# STM32WB06 register map
File version: 1.0
CPU: CM0+ r0p0, little endian, MPU, no FPU, 2 interrupt priority bits
Registers are 32-bit, read-write, reset 0x0 unless marked. A register's access mark holds for its fields unless they carry their own. Offsets are from the block's base; [hi:lo] are bit positions; {n}, {i} and the like mark numbered series.

## PKA
Base 0x48300000
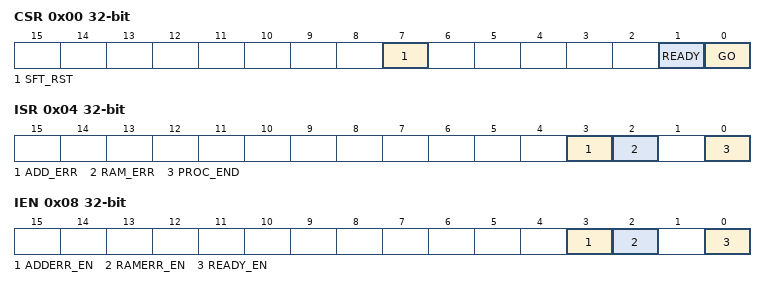
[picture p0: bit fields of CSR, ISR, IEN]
0x00 CSR — PKA_CSR register
  [7] SFT_RST — PKA software reset. Writing 0 clears the bit and releases the PKA block reset. Writing 1 resets the PKA block. The PKA RAM content is not changed.
  [1] READY ro — PKA readiness status. 0: The PKA is still computing 1: The PKA is ready to start a new calculation
  [0] GO — PKA start processing command. Writing 0 has no effect Writing 1 starts the encryption engine
0x04 ISR — PKA_ISR register
  [3] ADD_ERR — AHB Address error interrupt.
  [2] RAM_ERR — RAM read / write access error interrupt.
  [0] PROC_END — PKA process ending interrupt. When read: 0: No new event detected 1: The PKA process is ended (This bit is set to 1 when the PKA_CSR.READY bit rises.) When written: To clear the pending interrupt, the user must write this bit to 1 and clear it just after by writing 0. If the write 0 does not occur, the interrupt is generated on next event towards the CPU if enabled in PKA_IER but the flag is seen at 0 when the interrupt handler reads it in this register (as clear action is still active).
0x08 IEN — PKA_IEN register
  [3] ADDERR_EN — AHB Address error interrupt enable.
  [2] RAMERR_EN — RAM access error interrupt enable.
  [0] READY_EN — READY interrupt enable.

## GPIOB
Base 0x48100000
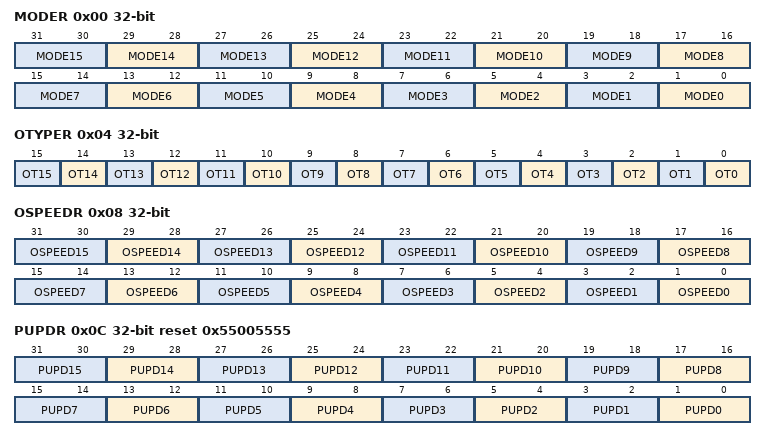
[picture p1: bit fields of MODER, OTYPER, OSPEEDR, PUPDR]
0x00 MODER
  [2n+1:2n] MODE{n} (n=0..15) — Port x configuration pin {n}
    0=Input mode; 1=Output (General purpose output mode); 2=Alternate function mode; 3=Analog mode
0x04 OTYPER
  [n] OT{n} (n=0..15) — Port x configuration pin {n}
    0=PushPull (Output push-pull (reset state)); 1=OpenDrain (Output open-drain)
0x08 OSPEEDR
  [2n+1:2n] OSPEED{n} (n=0..15) — Port x configuration pin {n}
    0=LowSpeed; 1=MediumSpeed; 2=HighSpeed; 3=VeryHighSpeed
0x0C PUPDR reset 0x55005555
  [2n+1:2n] PUPD{n} (n=0..15) — Port x configuration pin {n}
    0=Floating (No pull-up, pull-down); 1=PullUp; 2=PullDown
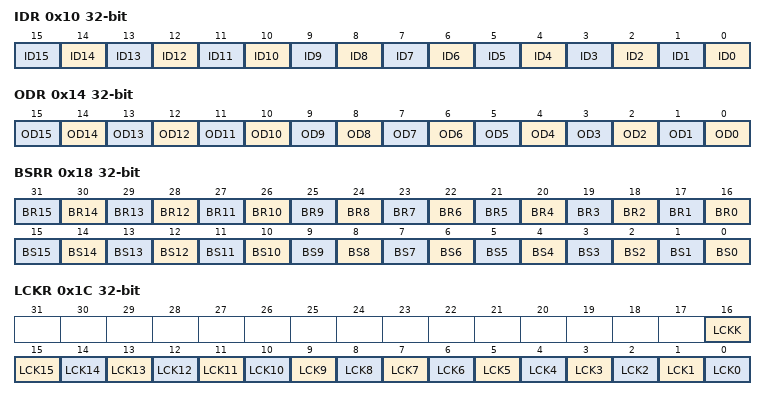
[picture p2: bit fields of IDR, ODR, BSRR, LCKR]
0x10 IDR ro (reset mask 0xFFFF0000)
  [n] ID{n} (n=0..15) — Port input data pin {n}
    0=Low (Input is logic low); 1=High (Input is logic high)
0x14 ODR
  [n] OD{n} (n=0..15) — Port output data pin {n}
    0=Low (Set output to logic low); 1=High (Set output to logic high)
0x18 BSRR wo
  [n+16] BR{n} (n=0..15) — Port x reset pin {n}
    1=Resets the corresponding ODx bit
  [n] BS{n} (n=0..15) — Port x set pin {n}
    1=Set (Sets the corresponding ODx bit)
0x1C LCKR
  [16] LCKK — Lock key This bit can be read any time. It can only be modified using the lock key write sequence. LOCK key write sequence: WR LCKR[16] = '1' + LCKR[15:0] WR LCKR[16] = '0' + LCKR[15:0] WR LCKR[16] = '1' + LCKR[15:0] RD LCKR RD LCKR[16] = '1' (this read operation is optional but it confirms that the lock is active) Note: During the LOCK key write sequence, the value of LCK[15:0] must not change. Note: Any error in the lock sequence aborts the lock. Note: After the first lock sequence on any bit of the port, any read access on the LCKK bit returns '1' until the next MCU reset or peripheral reset.
    0=NotActive (Port configuration lock key not active); 1=Active (Port configuration lock key active)
  [n] LCK{n} (n=0..15) — Port x lock pin {n}
    0=Unlocked (Port configuration not locked); 1=Locked (Port configuration locked)
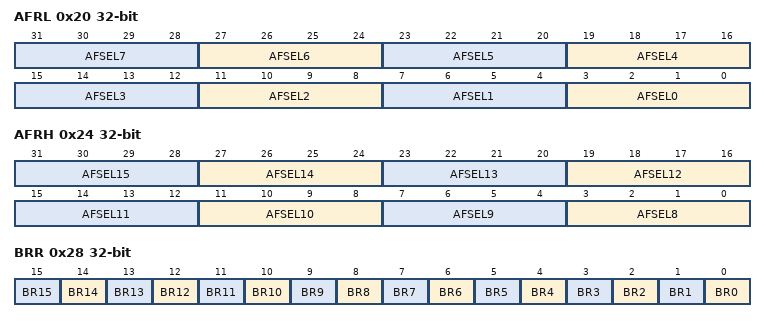
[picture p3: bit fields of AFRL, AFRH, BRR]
0x20 AFRL
  [4n+3:4n] AFSEL{n} (n=0..7) — Alternate function selection for port x I/O pin y These bits are written by software to configure alternate function I/Os.
    {v}=AF{v} (v=0..15)
0x24 AFRH
  [4n-29:4n-32] AFSEL{n} (n=8..15) — Alternate function selection for port x I/O pin y These bits are written by software to configure alternate function I/Os.
    {v}=AF{v} (v=0..15)
0x28 BRR wo
  [n] BR{n} (n=0..15) — Port x reset pin {n}
    0=No action on the corresponding ODx bit; 1=Reset the ODx bit

## IWDG
Base 0x40003000
0x00 KR 16-bit — IWDG_KR register
  [15:0] KEY wo — Key value. Software can only write these bits. Reading returns the reset value. These bits must be written by software at regular intervals with the key value 0xAAAA, otherwise the watchdog generates a reset when the counter reaches 0. Writing the key value 0x5555 to enables access to the IWDG_PR, IWDG_RLR and IWDG_WINR registers. Writing the key value CCCCh starts the watchdog
    0x5555=Unlock (Enable access to PR, RLR and WINR registers); 0xAAAA=Feed watchdog with RLR register value; 0xCCCC=Start the watchdog
0x04 PR 16-bit — IWDG_PR register
  [2:0] PR — Prescaler divider. Set and reset by software. These bits are write access protected. They are written by software to select the prescaler divider feeding the counter clock. PVU bit of IWDG_SR must be reset in order to be able to change the prescaler divider. 000: divider/4 001: divider/8 010: divider/16 011: divider/32 100: divider/64 101: divider/128 110: divider/256 111: divider/256
    0=DivideBy4 (Divider /4); 1=DivideBy8 (Divider /8); 2=DivideBy16 (Divider /16); 3=DivideBy32 (Divider /32); 4=DivideBy64 (Divider /64); 5=DivideBy128 (Divider /128); other=DivideBy256 (Divider /256)
0x08 RLR 16-bit reset 0xFFF — IWDG_RLR register
  [11:0] RL — Watchdog counter reload value. Set and reset by software. These bits are write access protected. They are written by software to define the value to be loaded in the watchdog counter each time the value 0xAAAA is written in the IWDG_KR register. The watchdog counter counts down from this value. The timeout period is a function of this value and the clock prescaler. The RVU bit in the IWDG_SR register must be reset in order to be able to change the reload value.
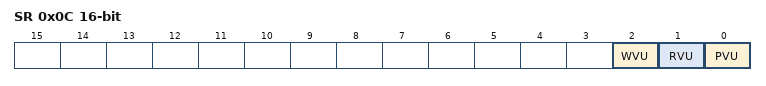
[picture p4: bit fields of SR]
0x0C SR 16-bit ro — IWDG_SR register
  [2] WVU — Watchdog counter window value update. Read only bit. This bit is set by hardware to indicate that an update of the window value is ongoing. It is reset by hardware when the reload value update operation is completed in the VDD voltage domain (takes up to 5 RC 40 kHz cycles). Window value can be updated only when WVU bit is reset. This bit is generated only if generic window = 1
  [1] RVU — Watchdog counter reload value update. Read only bit. This bit is set by hardware to indicate that an update of the reload value is ongoing. It is reset by hardware when the reload value update operation is completed in the VDD voltage domain (takes up to 5 RC 40 kHz cycles). Reload value can be updated only when RVU bit is reset
  [0] PVU — Watchdog prescaler value update. Read only bit. This bit is set by hardware to indicate that an update of the prescaler value is ongoing. It is reset by hardware when the prescaler update operation is completed in the VDD voltage domain (takes up to 5 RC 40 kHz cycles). Prescaler value can be updated only when PVU bit is reset
0x10 WINR 16-bit — IWDG_WINR register
  [11:0] WIN — Watchdog counter window value. Set and reset by software. These bits are write access protected. These bits contain the high limit of the window value to be compared to the downcounter. To prevent a reset, the downcounter must be reloaded when its value is lower than the window register value and greater than 0x0 The WVU bit in the IWDG_SR register must be reset in order to be able to change the reload value.
